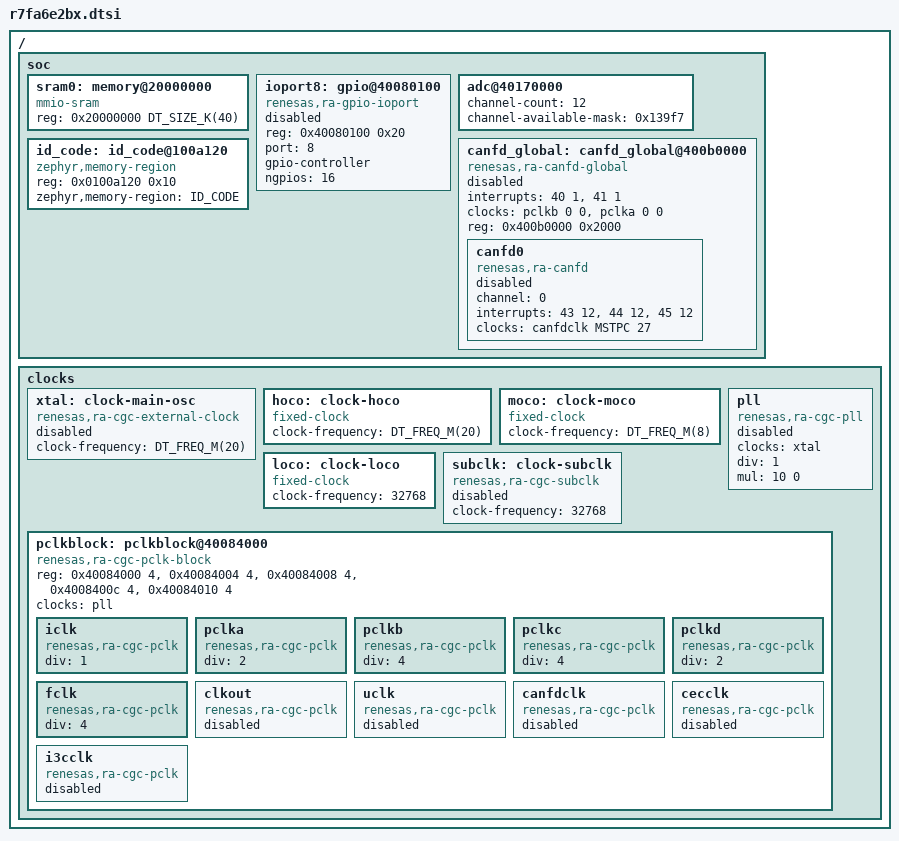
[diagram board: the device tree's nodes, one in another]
/*
 * Copyright (c) 2024 Renesas Electronics Corporation
 *
 * SPDX-License-Identifier: Apache-2.0
 */

#include <arm/renesas/ra/ra6/ra6-cm33-common.dtsi>
#include <zephyr/dt-bindings/clock/ra_clock.h>

/delete-node/ &agt0;
/delete-node/ &agt1;
/delete-node/ &agt2;
/delete-node/ &agt3;
/delete-node/ &agt4;
/delete-node/ &agt5;

/delete-node/ &adc1;

/ {
	soc {
		sram0: memory@20000000 {
			compatible = "mmio-sram";
			reg = <0x20000000 DT_SIZE_K(40)>;
		};

		ioport8: gpio@40080100 {
			compatible = "renesas,ra-gpio-ioport";
			reg = <0x40080100 0x20>;
			port = <8>;
			gpio-controller;
			#gpio-cells = <2>;
			ngpios = <16>;
			status = "disabled";
		};

		adc@40170000 {
			channel-count = <12>;
			channel-available-mask = <0x139f7>;
		};

		id_code: id_code@100a120 {
			compatible = "zephyr,memory-region";
			reg = <0x0100a120 0x10>;
			zephyr,memory-region = "ID_CODE";
			status = "okay";
		};

		canfd_global: canfd_global@400b0000 {
			compatible = "renesas,ra-canfd-global";
			interrupts = <40 1>, <41 1>;
			interrupt-names = "rxf", "glerr";
			clocks = <&pclkb 0 0>, <&pclka 0 0>;
			clock-names = "opclk", "ramclk";
			reg = <0x400b0000 0x2000>;
			status = "disabled";

			canfd0: canfd0 {
				compatible = "renesas,ra-canfd";
				channel = <0>;
				interrupts = <43 12>, <44 12>, <45 12>;
				interrupt-names = "err", "tx", "rx";
				clocks = <&canfdclk MSTPC 27>;
				clock-names = "dllclk";
				status = "disabled";
			};
		};
	};

	clocks: clocks {
		#address-cells = <1>;
		#size-cells = <1>;

		xtal: clock-main-osc {
			compatible = "renesas,ra-cgc-external-clock";
			clock-frequency = <DT_FREQ_M(20)>;
			#clock-cells = <0>;
			status = "disabled";
		};

		hoco: clock-hoco {
			compatible = "fixed-clock";
			clock-frequency = <DT_FREQ_M(20)>;
			#clock-cells = <0>;
		};

		moco: clock-moco {
			compatible = "fixed-clock";
			clock-frequency = <DT_FREQ_M(8)>;
			#clock-cells = <0>;
		};

		loco: clock-loco {
			compatible = "fixed-clock";
			clock-frequency = <32768>;
			#clock-cells = <0>;
		};

		subclk: clock-subclk {
			compatible = "renesas,ra-cgc-subclk";
			clock-frequency = <32768>;
			#clock-cells = <0>;
			status = "disabled";
		};

		pll: pll {
			compatible = "renesas,ra-cgc-pll";
			#clock-cells = <0>;

			/* PLL */
			clocks = <&xtal>;
			div = <1>;
			mul = <10 0>;
			status = "disabled";
		};

		pclkblock: pclkblock@40084000 {
			compatible = "renesas,ra-cgc-pclk-block";
			reg = <0x40084000 4>, <0x40084004 4>, <0x40084008 4>,
			      <0x4008400c 4>, <0x40084010 4>;
			reg-names = "MSTPA", "MSTPB","MSTPC",
				    "MSTPD", "MSTPE";
			#clock-cells = <0>;
			clocks = <&pll>;
			status = "okay";

			iclk: iclk {
				compatible = "renesas,ra-cgc-pclk";
				div = <1>;
				#clock-cells = <2>;
				status = "okay";
			};

			pclka: pclka {
				compatible = "renesas,ra-cgc-pclk";
				div = <2>;
				#clock-cells = <2>;
				status = "okay";
			};

			pclkb: pclkb {
				compatible = "renesas,ra-cgc-pclk";
				div = <4>;
				#clock-cells = <2>;
				status = "okay";
			};

			pclkc: pclkc {
				compatible = "renesas,ra-cgc-pclk";
				div = <4>;
				#clock-cells = <2>;
				status = "okay";
			};

			pclkd: pclkd {
				compatible = "renesas,ra-cgc-pclk";
				div = <2>;
				#clock-cells = <2>;
				status = "okay";
			};

			fclk: fclk {
				compatible = "renesas,ra-cgc-pclk";
				div = <4>;
				#clock-cells = <2>;
				status = "okay";
			};

			clkout: clkout {
				compatible = "renesas,ra-cgc-pclk";
				#clock-cells = <2>;
				status = "disabled";
			};

			uclk: uclk {
				compatible = "renesas,ra-cgc-pclk";
				#clock-cells = <2>;
				status = "disabled";
			};

			canfdclk: canfdclk {
				compatible = "renesas,ra-cgc-pclk";
				#clock-cells = <2>;
				status = "disabled";
			};

			cecclk: cecclk {
				compatible = "renesas,ra-cgc-pclk";
				#clock-cells = <2>;
				status = "disabled";
			};

			i3cclk: i3cclk {
				compatible = "renesas,ra-cgc-pclk";
				#clock-cells = <2>;
				status = "disabled";
			};
		};
	};
};
